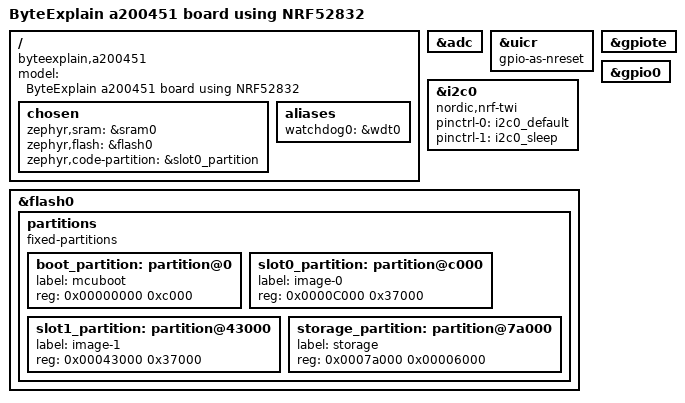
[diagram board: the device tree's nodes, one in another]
/*
 * Copyright (c) 2017 Shawn Nock <shawn@monadnock.ca>
 * Copyright (c) 2017 Linaro Limited
 *
 * SPDX-License-Identifier: Apache-2.0
 */

/dts-v1/;
#include <nordic/nrf52832_qfaa.dtsi>
#include "a200451-pinctrl.dtsi"
#include <zephyr/dt-bindings/input/input-event-codes.h>

/ {
	model = "ByteExplain a200451 board using NRF52832";
	compatible = "byteexplain,a200451";

	chosen {
		zephyr,sram = &sram0;
		zephyr,flash = &flash0;
		zephyr,code-partition = &slot0_partition;
	};

	/* These aliases are provided for compatibility with samples */
	aliases {
		watchdog0 = &wdt0;
	};
};

&adc {
	status = "okay";
};

&uicr {
	gpio-as-nreset;
};

&gpiote {
	status = "okay";
};

&gpio0 {
	status = "okay";
};

&i2c0 {
	compatible = "nordic,nrf-twi";
	status = "okay";
	pinctrl-0 = <&i2c0_default>;
	pinctrl-1 = <&i2c0_sleep>;
	pinctrl-names = "default", "sleep";
};

&flash0 {

	partitions {
		compatible = "fixed-partitions";
		#address-cells = <1>;
		#size-cells = <1>;

		boot_partition: partition@0 {
			label = "mcuboot";
			reg = <0x00000000 0xc000>;
		};
		slot0_partition: partition@c000 {
			label = "image-0";
			reg = <0x0000C000 0x37000>;
		};
		slot1_partition: partition@43000 {
			label = "image-1";
			reg = <0x00043000 0x37000>;
		};
		storage_partition: partition@7a000 {
			label = "storage";
			reg = <0x0007a000 0x00006000>;
		};
	};
};
